VERSION ""

NS_ :

BS_:

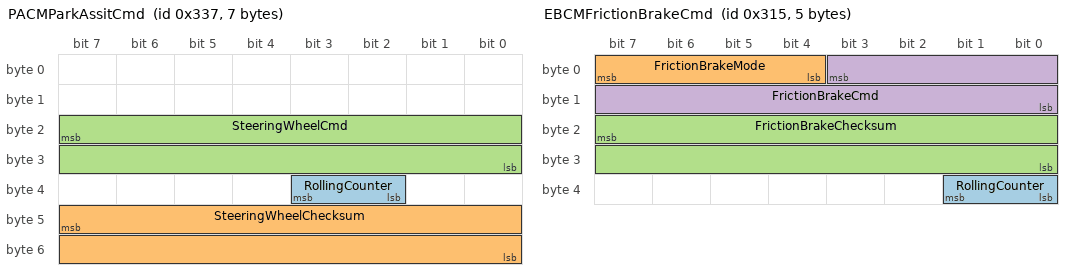
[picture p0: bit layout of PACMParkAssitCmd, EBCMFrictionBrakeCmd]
BO_ 823 PACMParkAssitCmd: 7 NEO
 SG_ RollingCounter : 35|2@0+ (1,0) [0|0] ""  NEO
 SG_ SteeringWheelChecksum : 47|16@0+ (1,0) [0|0] ""  NEO
 SG_ SteeringWheelCmd : 23|16@0+ (1,0) [0|0] ""  NEO

BO_ 560 EBCMRegen: 6 K17_EBCM
 SG_ Regen : 1|10@0+ (1,0) [0|0] ""  NEO

BO_ 368 EBCMFrictionBrakeStatus: 8 K17_EBCM
 SG_ FrictionBrakePressure : 23|16@0+ (1,0) [0|0] ""  NEO

BO_ 789 EBCMFrictionBrakeCmd: 5 K17_EBCM
 SG_ RollingCounter : 33|2@0+ (1,0) [0|0] ""  NEO
 SG_ FrictionBrakeMode : 7|4@0+ (1,0) [0|0] ""  NEO
 SG_ FrictionBrakeChecksum : 23|16@0+ (1,0) [0|0] ""  NEO
 SG_ FrictionBrakeCmd : 3|12@0- (1,0) [0|0] ""  NEO

BO_TX_BU_ 823 : K43_PSCM,NEO;
BO_TX_BU_ 789 : NEO,K17_EBCM;

BU_: Airbag_MQB BAP_Tester_MQB BMS_MQB Datenlogger_MQB Gateway_MQB Getriebe_DQ_Hybrid_MQB Getriebe_DQ_MQB LEH_MQB Motor_Diesel_MQB Motor_Hybrid_MQB Motor_Otto_MQB SAK_MQB Waehlhebel_MQB Vector__XXX l c i XXX

CM_ "AUTOGENERATED FILE, DO NOT EDIT";

CM_ "Imported file _comma.dbc starts here";
CM_ "Imported file _honda_common.dbc starts here";
CM_ SG_ 304 "Seems to be platform-agnostic";
CM_ SG_ 316 "Should exist on Nidec";
CM_ SG_ 420 BRAKE_HOLD_RELATED "On when Brake Hold engaged";
CM_ SG_ 490 LONG_ACCEL "wheel speed derivative, noisy and zero snapping";
CM_ SG_ 773 PASS_AIRBAG_ON "Might just be indicator light";
CM_ SG_ 773 PASS_AIRBAG_OFF "Might just be indicator light";
CM_ SG_ 780 CRUISE_SPEED "255 = no speed";
CM_ SG_ 780 PCM_SPEED "Used by Nidec";
CM_ SG_ 780 PCM_GAS "Used by Nidec";
CM_ SG_ 804 CRUISE_SPEED_PCM "255 = no speed";

CM_ "Imported file _nidec_common.dbc starts here";
CM_ SG_ 506 AEB_REQ_1 "set for duration of suspected AEB event";
CM_ SG_ 506 COMPUTER_BRAKE_ALT "Used by dual-can Nidec";
CM_ SG_ 506 BRAKE_PUMP_REQUEST_ALT "Used by dual-can Nidec";
CM_ SG_ 829 BEEP "beeps are pleasant, chimes are for warnngs etc...";

CM_ "Imported file _steering_sensors_b.dbc starts here";
CM_ "honda_odyssey_exl_2018.dbc starts here";

CM_ SG_ 419 GEAR "10 = reverse, 11 = transition";
CM_ SG_ 780 CRUISE_SPEED "255 = no speed";
CM_ SG_ 806 REVERSE_LIGHT "Might be reverse gear selected and not the lights";

VAL_ 870 AWV_Text 0 "kein_Text" 1 "FrontAssist_aus" 2 "FrontAssist_startet" 3 "FrontAssist_Warnung" 4 "FrontAssist_Sens_reinig" 5 "FrontAssist_Failure" 6 "FrontAssist_Demo" 7 "Vorhalt" 8 "Bremsung_wird_gerade_durchgefuehrt" 9 "Sensor_not_verfuegbar" 10 "Sensor_reinigen" 11 "Service_notwendig_Failure" 12 "Funktion_vom_Fahrer_deactivated" 13 "Funktion_vom_Fahrer_activated" 14 "FrontAssist_zur_Zeit_not_verfuegbar__rev_Failure";
VAL_ 870 AWV_1_Freigabe 0 "nicht_freigegeben" 1 "freigegeben";
VAL_ 870 AWV_1_Prefill 0 "keine_Prefill_Anf" 1 "Prefill_Anf";
VAL_ 870 AWV_1_Parameter 0 "Defaultparametersatz" 1 "Par_leicht_erh_Empf" 2 "Par_erh_Empf" 3 "Par_hoechster_Empf";
VAL_ 870 AWV_only 0 "ACC_und_AWV_verbaut" 1 "AWV_ohne_ACC_verbaut";
VAL_ 870 AWV_CityANB_Auspraegung 0 "autom_Bremsung_im_ges_vBereich" 1 "autom_Bremsung_im_def_vBereich";
VAL_ 870 AWV_Halten 0 "keine_Anforderung" 1 "Anforderung_das_Fzg_im_Stillstand_zu_halten";
VAL_ 870 ANB_Teilbremsung_Freigabe 0 "Teilbremsung_nicht_freigegeben" 1 "Teilbremsung_freigegeben";
VAL_ 870 AWV_2_Status 0 "Lampe_aus" 1 "Lampe_ein";
VAL_ 870 AWV_2_Fehler 0 "Lampe_aus" 1 "Lampe_ein";
VAL_ 870 AWV_2_SU_Warnzeit 0 "frueh" 1 "normal" 2 "spaet" 3 "adaptiv";
VAL_ 870 AWV_2_SU_Bremsruck 0 "Bremsruck_deaktiviert" 1 "Bremsruck_aktiviert";
VAL_ 870 AWV_2_SU_Gong 0 "Gong_deaktiviert" 1 "Gong_aktiviert";
VAL_ 870 AWV_2_SU_Lampe 0 "Lampe_deaktiviert" 1 "Lampe_aktiviert";
VAL_ 870 AWV_2_Umfeldwarn 0 "keine_Warnung" 1 "Warnung";
VAL_ 870 AWV_2_Freigabe 0 "keine_Ruckfreigabe" 1 "Ruckfreigabe";
VAL_ 870 AWV_2_Ruckprofil 0 "kein_Ruck" 1 "Ruckprofil_1" 2 "Ruckprofil_2" 3 "Ruckprofil_3" 4 "Ruckprofil_4" 5 "Ruckprofil_5" 6 "not_erlaubt" 7 "not_erlaubt";
VAL_ 870 AWV_2_Warnton 0 "Aus" 1 "Ein";
VAL_ 870 AWV_2_Warnsymbol 0 "Aus" 1 "Ein";
VAL_ 870 AWV_Infoton 0 "Aus" 1 "Ein";
VAL_ 870 AWV_2_Gurtstraffer 0 "Gurt_not_straffen" 1 "Gurt_straffen";
VAL_ 870 AWV_Konfiguration_Menueanf 0 "Menue_deaktivieren" 1 "Menue_aktivieren";
VAL_ 870 AWV_Konfiguration_Vorw_Menueanf 0 "Menue_deaktivieren" 1 "Menue_aktivieren";
VAL_ 870 AWV_Konfiguration_Status 0 "AWV_inaktiv" 1 "AWV_aktiv";
VAL_ 870 AWV_Konfiguration_Vorw_Status 0 "AWV_Vorwarnung_inaktiv" 1 "AWV_Vorwarnung_aktiv";
VAL_ 870 AWV_2_Abstandswarnung 0 "kein_Warnhinweis" 1 "Warnhinweis";
VAL_ 870 ANB_Zielbremsung_Freigabe 0 "Zielbremsung_nicht_freigegeben" 1 "Zielbremsung_freigegeben";
VAL_ 870 ANB_CM_Anforderung 0 "keine_Anforderung" 1 "Anforderung_aktiv";

VAL_ 872 ACS_Sta_ADR 2 "ADR_passiv" 0 "ADR_nicht_aktiv" 1 "ADR_aktiv" 3 "irrev_Fehler" ;
VAL_ 872 ACS_ADR_Schub 1 "Verz_begr_auf_Schub" 0 "Verz_nicht_begr_auf_Schub" ;
VAL_ 872 ACS_Schubabsch 1 "SA_nicht_zulaessig" 0 "SA_zulaessig" ;
VAL_ 872 ACS_StSt_Info 3 "Systemfehler" 0 "Motorlauf_nn" 1 "Stoppverbot_Motoranlauf_nn" 2 "Motoranlauf_notwendig" ;
VAL_ 872 ACS_MomEingriff 1 "MomEingr_verhindern" 0 "keine_Beeinfl_MomEingr_Mot" ;
VAL_ 872 ACS_Typ_ACC 0 "Basis_ACC" 1 "ACC_mit_FollowToStop" 3 "frei" 2 "frei" ;
VAL_ 872 ACS_FreigSollB 0 "Sollbeschl_nicht_freigeg" 1 "Sollbeschl_freigeg" ;
VAL_ 872 ACS_Sollbeschl 2046 "ADR_nicht_aktiv" 2047 "Fehler" ;
VAL_ 872 ACS_Anhaltewunsch 0 "kein_Haltewunsch" 1 "Fzg_haelt_an" ;
VAL_ 872 ACS_Fehler 1 "Fehlerspeichereintrag" 0 "kein_Fehlerspeichereintrag" ;
VAL_ 872 ACS_zul_Regelabw 254 "ADR_nicht_aktiv" 255 "Fehler" ;
VAL_ 872 ACS_max_AendGrad 254 "Neutralwert" 0 "Neutralwert" 255 "Fehler" ;

VAL_ 978 LH2_Sta_HCA 0 "disabled" 1 "initializing" 2 "fault" 3 "ready" 4 "rejected" 5 "active";
VAL_ 1088 Waehlhebelposition__Getriebe_1_ 8 "P" 7 "R" 6 "N" 5 "D" 9 "U" 12 "S" 14 "T" 10 "T" 11 "T";

VAL_ 1386 ACA_StaACC 6 "ACC_rev_aus" 0 "Hauptschalter_aus" 4 "ACC_im_Hintergrund" 3 "ACC_aktiv" 1 "Reserve" 2 "ACC_passiv" 7 "ACC_irrev_aus" 5 "frei" ;
VAL_ 1386 ACA_ID_StaACC 0 "keine_Anzeige" ;
VAL_ 1386 ACA_Fahrerhinw 1 "Ein" 0 "Aus" ;
VAL_ 1386 ACA_AnzDisplay 1 "Anzeige_erw" 0 "Anzeige_nicht_erw" ;
VAL_ 1386 ACA_Zeitluecke 3 "Zeitluecke3" 10 "Zeitluecke10" 4 "Zeitluecke4" 14 "Zeitluecke14" 11 "Zeitluecke11" 2 "Zeitluecke2" 13 "Zeitluecke13" 9 "Zeitluecke9" 1 "Zeitluecke1" 8 "Zeitluecke8" 5 "Zeitluecke5" 15 "Zeitluecke15" 0 "nicht_definiert" 12 "Zeitluecke12" 6 "Zeitluecke6" 7 "Zeitluecke7" ;
VAL_ 1386 ACA_V_Wunsch 255 "kein_Wert_im_Speicher" ;
VAL_ 1386 ACA_kmh_mph 0 "km_h" 1 "mph" ;
VAL_ 1386 ACA_Akustik1 0 "kein_Gong" 1 "Gong" ;
VAL_ 1386 ACA_Akustik2 0 "kein_Summer" 1 "Summer" ;
VAL_ 1386 ACA_PrioDisp 1 "mittlere_Prio" 3 "keine_Anzeige_Anf" 0 "hohe_Prio" 2 "niedrige_Prio" ;
VAL_ 1386 ACA_gemZeitl 6 "Zeitluecke6" 2 "Zeitluecke2" 7 "Zeitluecke7" 13 "Zeitluecke13" 11 "Zeitluecke11" 4 "Zeitluecke4" 8 "Zeitluecke8" 12 "Zeitluecke12" 10 "Zeitluecke10" 0 "Kein_Objekt_erfasst" 1 "Zeitluecke1" 3 "Zeitluecke3" 9 "Zeitluecke9" 15 "Zeitluecke15" 14 "Zeitluecke14" 5 "Zeitluecke5" ;
VAL_ 1386 ACA_ACC_Verz 0 "ACC_verzoegert_nicht" 1 "ACC_verzoegert" ;
VAL_ 1386 ACA_StaGRA 3 "GRA_aktiv" 4 "GRA_uebertreten" 2 "GRA_passiv" 0 "Hauptschalter_aus" 6 "frei" 7 "GRA_Fehler" 1 "Reserve" 5 "frei" ;
VAL_ 1386 ACA_ID_StaGRA 0 "keine_Anzeige" ;
VAL_ 1386 ACA_Codierung 0 "ACC" 1 "GRA" ;
VAL_ 1386 ACA_Tachokranz 0 "nicht_beleuchtet" 1 "beleuchtet" ;
VAL_ 1386 ACA_Aend_Zeitluecke 1 "Anzeige_angef" 0 "keine_Anzeige" ;

VAL_ 1472 EP1_Fehler_Sta 0 "volle_Funktion" 1 "linke_Seite_fehlerhaft" 2 "rechte_Seite_fehlerhaft" 3 "beide_Seiten_fehlerhaft";
VAL_ 1472 EP1_Sta_EPB 0 "Bremse_geoeffnet" 1 "Bremse_geschlossen";
VAL_ 1472 EP1_Sta_Schalter 0 "volle_Funktion" 1 "Schalter_ausser_Funktion";
VAL_ 1472 EP1_Spannkraft 31 "Fehler";
VAL_ 1472 EP1_Schalterinfo 0 "keine_Fahreranforderung" 1 "Fahreranforderung_oeffnen" 2 "Fahreranforderung_schliessen" 3 "Schalterfehler";
VAL_ 1472 EP1_Sta_NWS 0 "volle_Funktion" 1 "keine_Funktion";
VAL_ 1472 EP1_Fehlereintr 0 "kein_Fehlerspeichereintrag" 1 "Fehlerspeichereintrag";
VAL_ 1472 EP1_Freigabe_Ver 0 "Verzoegerungsanf_nicht_freigegeb" 1 "Verzoegerungsanf_freigegeben";
VAL_ 1472 EP1_AutoHold_zul 0 "Pers_nicht_zulaessig" 1 "Pers_zulaessig";
VAL_ 1472 EP1_AutoHold_aktiv 0 "nein" 1 "ja";
VAL_ 1472 EP1_SleepInd 0 "CAN_wird_benoetigt" 1 "Sleep_bereit";
VAL_ 1472 EP1_Status_Kl_15 0 "Kl_15_aus" 1 "Kl_15_ein";
VAL_ 1472 EP1_Lampe_AutoP 0 "Lampe_aus" 1 "Lampe_ein";
VAL_ 1472 EP1_Bremslicht 0 "Aus" 1 "Ein";
VAL_ 1472 EP1_Warnton1 0 "Aus" 1 "Ein";
VAL_ 1472 EP1_Warnton2 0 "Aus" 1 "Ein";
VAL_ 1472 EP1_AnfShLock 0 "Aus" 1 "Ein";
VAL_ 1472 EPB_Autoholdlampe 0 "Lampe_aus" 1 "Lampe_ein";
VAL_ 1472 EP1_QualNeigWi 0 "gueltiger_Wert" 1 "Ersatz_Init_oder_Fehlerwert";
VAL_ 1472 EP1_KuppModBer 0 "Kuppsensor_aus_Modbereich" 1 "Kupplsensor_im_Modbereich" 2 "Sensorsignal_ungenau" 3 "Sensor_defekt";
VAL_ 1472 EP1_HydrHalten 0 "Fzg_nicht_hydr_geh" 1 "Fzg_hydr_geh";
VAL_ 1472 EP1_Fkt_Lampe 0 "Lampe_aus" 1 "Lampe_ein";
VAL_ 1472 EP1_Warnton 0 "Warnton_aus" 1 "Warnton_an";
VAL_ 1472 EP1_Fehler_BKL 0 "BKL_aus" 1 "BKL_an";
VAL_ 1472 EP1_Fehler_gelb 0 "Lampe_aus" 1 "Lampe_ein";
